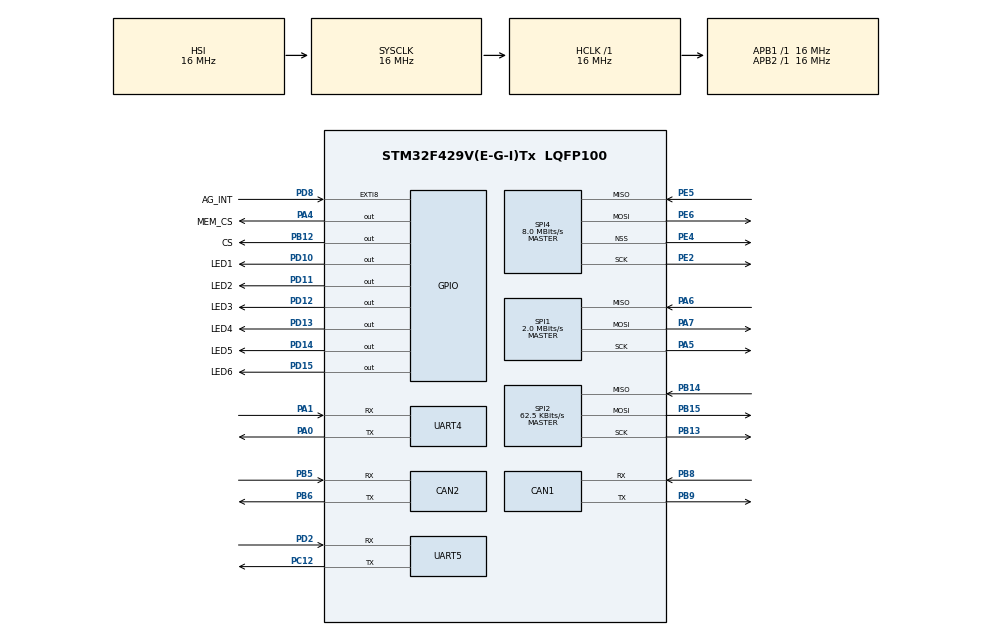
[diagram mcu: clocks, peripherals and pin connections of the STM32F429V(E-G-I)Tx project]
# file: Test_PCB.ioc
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CAN1.BS1=CAN_BS1_1TQ
CAN1.BS2=CAN_BS2_1TQ
CAN1.CalculateTimeBit=3000
CAN1.CalculateTimeQuantum=1000.0
CAN2.BS1=CAN_BS1_1TQ
CAN2.BS2=CAN_BS2_1TQ
CAN2.CalculateTimeBit=3000
CAN2.CalculateTimeQuantum=1000.0
FREERTOS.Tasks01=defaultTask,0,128,StartDefaultTask,Default,NULL
Mcu.Family=STM32F4
Mcu.Name=STM32F429V(E-G-I)Tx
Mcu.Package=LQFP100
NVIC.PriorityGroup=NVIC_PRIORITYGROUP_4
NVIC.TIM1_UP_TIM10_IRQn=true\:0\:0\:false\:false\:true\:false\:false
NVIC.TIM3_IRQn=true\:5\:0\:false\:false\:true\:true\:true
NVIC.TimeBase=TIM1_UP_TIM10_IRQn
NVIC.TimeBaseIP=TIM1
PA0/WKUP.Mode=Asynchronous
PA0/WKUP.Signal=UART4_TX
PA1.Mode=Asynchronous
PA1.Signal=UART4_RX
PA13.Mode=JTAG_5_pins
PA13.Signal=SYS_JTMS-SWDIO
PA14.Mode=JTAG_5_pins
PA14.Signal=SYS_JTCK-SWCLK
PA15.Mode=JTAG_5_pins
PA15.Signal=SYS_JTDI
PA4.GPIO_Label=MEM_CS
PA4.Signal=GPIO_Output
PA5.Mode=Full_Duplex_Master
PA5.Signal=SPI1_SCK
PA6.Mode=Full_Duplex_Master
PA6.Signal=SPI1_MISO
PA7.Mode=Full_Duplex_Master
PA7.Signal=SPI1_MOSI
PB12.GPIO_Label=CS
PB12.Signal=GPIO_Output
PB13.Mode=Full_Duplex_Master
PB13.Signal=SPI2_SCK
PB14.Mode=Full_Duplex_Master
PB14.Signal=SPI2_MISO
PB15.Mode=Full_Duplex_Master
PB15.Signal=SPI2_MOSI
PB3.Mode=JTAG_5_pins
PB3.Signal=SYS_JTDO-SWO
PB4.Mode=JTAG_5_pins
PB4.Signal=SYS_JTRST
PB5.Mode=Slave
PB5.Signal=CAN2_RX
PB6.Mode=Slave
PB6.Signal=CAN2_TX
PB8.Mode=Master
PB8.Signal=CAN1_RX
PB9.Mode=Master
PB9.Signal=CAN1_TX
PC12.Mode=Asynchronous
PC12.Signal=UART5_TX
PD10.GPIO_Label=LED1
PD10.GPIO_PuPd=GPIO_NOPULL
PD10.Signal=GPIO_Output
PD11.GPIO_Label=LED2
PD11.GPIO_PuPd=GPIO_NOPULL
PD11.Signal=GPIO_Output
PD12.GPIO_Label=LED3
PD12.GPIO_PuPd=GPIO_NOPULL
PD12.Signal=GPIO_Output
PD13.GPIO_Label=LED4
PD13.GPIO_PuPd=GPIO_NOPULL
PD13.Signal=GPIO_Output
PD14.GPIO_Label=LED5
PD14.GPIO_PuPd=GPIO_NOPULL
PD14.Signal=GPIO_Output
PD15.GPIO_Label=LED6
PD15.GPIO_PuPd=GPIO_NOPULL
PD15.Signal=GPIO_Output
PD2.Mode=Asynchronous
PD2.Signal=UART5_RX
PD8.GPIO_Label=AG_INT
PD8.GPIO_ModeDefaultEXTI=GPIO_MODE_IT_FALLING
PD8.Signal=GPXTI8
PE2.Mode=Full_Duplex_Master
PE2.Signal=SPI4_SCK
PE4.Mode=NSS_Signal_Hard_Output
PE4.Signal=SPI4_NSS
PE5.Mode=Full_Duplex_Master
PE5.Signal=SPI4_MISO
PE6.Mode=Full_Duplex_Master
PE6.Signal=SPI4_MOSI
PH0/OSC_IN.Mode=HSE-External-Oscillator
PH0/OSC_IN.Signal=RCC_OSC_IN
PH1/OSC_OUT.Mode=HSE-External-Oscillator
PH1/OSC_OUT.Signal=RCC_OSC_OUT
ProjectManager.HeapSize=0x200
ProjectManager.StackSize=0x400
ProjectManager.TargetToolchain=SW4STM32
RCC.AHBFreq_Value=16000000
RCC.APB1Freq_Value=16000000
RCC.APB1TimFreq_Value=16000000
RCC.APB2Freq_Value=16000000
RCC.APB2TimFreq_Value=16000000
RCC.CortexFreq_Value=16000000
RCC.HCLKFreq_Value=16000000
RCC.HSE_VALUE=16000000
RCC.HSI_VALUE=16000000
RCC.LSE_VALUE=32768
RCC.SYSCLKFreq_VALUE=16000000
RCC.VCOOutputFreq_Value=192000000
SPI1.BaudRatePrescaler=SPI_BAUDRATEPRESCALER_8
SPI1.CalculateBaudRate=2.0 MBits/s
SPI1.Direction=SPI_DIRECTION_2LINES
SPI1.Mode=SPI_MODE_MASTER
SPI1.VirtualType=VM_MASTER
SPI2.BaudRatePrescaler=SPI_BAUDRATEPRESCALER_256
SPI2.CalculateBaudRate=62.5 KBits/s
SPI2.DataSize=SPI_DATASIZE_16BIT
SPI2.Direction=SPI_DIRECTION_2LINES
SPI2.Mode=SPI_MODE_MASTER
SPI2.VirtualType=VM_MASTER
SPI4.BaudRatePrescaler=SPI_BAUDRATEPRESCALER_2
SPI4.CalculateBaudRate=8.0 MBits/s
SPI4.Direction=SPI_DIRECTION_2LINES
SPI4.Mode=SPI_MODE_MASTER
SPI4.VirtualNSS=VM_NSSHARD
SPI4.VirtualType=VM_MASTER
TIM3.Period=1000
TIM3.Prescaler=16000
UART4.VirtualMode=Asynchronous
UART5.VirtualMode=Asynchronous
VP_FREERTOS_VS_ENABLE.Mode=Enabled
VP_SYS_VS_tim1.Mode=TIM1
VP_TIM3_VS_ClockSourceINT.Mode=Internal
board=Test_PCB

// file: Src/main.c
/**
  ******************************************************************************
  * File Name          : main.c
  * Description        : Main program body
  ******************************************************************************
  * This notice applies to any and all portions of this file
  * that are not between comment pairs USER CODE BEGIN and
  * USER CODE END. Other portions of this file, whether
  * inserted by the user or by software development tools
  * are owned by their respective copyright owners.
  *
  * Copyright (c) 2018 STMicroelectronics International N.V.
  * All rights reserved.
  *
  * Redistribution and use in source and binary forms, with or without
  * modification, are permitted, provided that the following conditions are met:
  *
  * 1. Redistribution of source code must retain the above copyright notice,
  *    this list of conditions and the following disclaimer.
  * 2. Redistributions in binary form must reproduce the above copyright notice,
  *    this list of conditions and the following disclaimer in the documentation
  *    and/or other materials provided with the distribution.
  * 3. Neither the name of STMicroelectronics nor the names of other
  *    contributors to this software may be used to endorse or promote products
  *    derived from this software without specific written permission.
  * 4. This software, including modifications and/or derivative works of this
  *    software, must execute solely and exclusively on microcontroller or
  *    microprocessor devices manufactured by or for STMicroelectronics.
  * 5. Redistribution and use of this software other than as permitted under
  *    this license is void and will automatically terminate your rights under
  *    this license.
  *
  * THIS SOFTWARE IS PROVIDED BY STMICROELECTRONICS AND CONTRIBUTORS "AS IS"
  * AND ANY EXPRESS, IMPLIED OR STATUTORY WARRANTIES, INCLUDING, BUT NOT
  * LIMITED TO, THE IMPLIED WARRANTIES OF MERCHANTABILITY, FITNESS FOR A
  * PARTICULAR PURPOSE AND NON-INFRINGEMENT OF THIRD PARTY INTELLECTUAL PROPERTY
  * RIGHTS ARE DISCLAIMED TO THE FULLEST EXTENT PERMITTED BY LAW. IN NO EVENT
  * SHALL STMICROELECTRONICS OR CONTRIBUTORS BE LIABLE FOR ANY DIRECT, INDIRECT,
  * INCIDENTAL, SPECIAL, EXEMPLARY, OR CONSEQUENTIAL DAMAGES (INCLUDING, BUT NOT
  * LIMITED TO, PROCUREMENT OF SUBSTITUTE GOODS OR SERVICES; LOSS OF USE, DATA,
  * OR PROFITS; OR BUSINESS INTERRUPTION) HOWEVER CAUSED AND ON ANY THEORY OF
  * LIABILITY, WHETHER IN CONTRACT, STRICT LIABILITY, OR TORT (INCLUDING
  * NEGLIGENCE OR OTHERWISE) ARISING IN ANY WAY OUT OF THE USE OF THIS SOFTWARE,
  * EVEN IF ADVISED OF THE POSSIBILITY OF SUCH DAMAGE.
  *
  ******************************************************************************
  */
#include "mems.h"
#include "debug.h"
#include "main.h"
#include "stm32f4xx_hal.h"
#include "cmsis_os.h"

/* USER CODE BEGIN Includes */
//#include "gyro.h"
//#include "memory.h"
/* USER CODE END Includes */

CAN_HandleTypeDef hcan1;
CAN_HandleTypeDef hcan2;

SPI_HandleTypeDef hspi1;
SPI_HandleTypeDef hspi2;
SPI_HandleTypeDef hspi4;

TIM_HandleTypeDef htim3;

UART_HandleTypeDef huart4;
UART_HandleTypeDef huart5;

osThreadId defaultTaskHandle;

/* USER CODE BEGIN PV */
/* Private variables ---------------------------------------------------------*/
int tgl=0;
char test[64];
osThreadId receiveUARTHandle;
osThreadId sendUARTHandle;
/* USER CODE END PV */

void SystemClock_Config(void);
static void MX_GPIO_Init(void);
static void MX_CAN1_Init(void);
static void MX_CAN2_Init(void);
static void MX_SPI1_Init(void);
static void MX_UART4_Init(void);
static void MX_UART5_Init(void);
static void MX_SPI4_Init(void);
static void MX_SPI2_Init(void);
static void MX_TIM3_Init(void);
void StartDefaultTask(void const * argument);

/* USER CODE BEGIN PFP */
/* Private function prototypes -----------------------------------------------*/
//void receiveUARTTask(void const * argument);
//void sendUARTTask(void const * argument);
/* USER CODE END PFP */

int main(void)
{

  /* MCU Configuration----------------------------------------------------------*/

  /* Reset of all peripherals, Initializes the Flash interface and the Systick. */
  HAL_Init();

  /* Configure the system clock */
  SystemClock_Config();

  /* Initialize all configured peripherals */
  MX_GPIO_Init();
  MX_CAN1_Init();
  MX_CAN2_Init();
  MX_SPI1_Init();
  MX_UART4_Init();
  MX_UART5_Init();
  MX_SPI4_Init();
  MX_SPI2_Init();
  MX_TIM3_Init();

  /* USER CODE BEGIN 2 */
  mems_init8b(&huart4,&hspi2); //init gyro

  /* USER CODE END 2 */

  /* Create the thread(s) */
  /* definition and creation of defaultTask */
  osThreadDef(defaultTask, StartDefaultTask, osPriorityNormal, 0, 128);
  defaultTaskHandle = osThreadCreate(osThread(defaultTask), NULL);

  /* USER CODE BEGIN RTOS_THREADS */
  /* add threads, ... */

//  osThreadDef(receiveTask, receiveUARTTask, osPriorityNormal, 0, 128);
//  receiveUARTHandle = osThreadCreate(osThread(receiveTask), NULL);
//
//  osThreadDef(sendTask, sendUARTTask, osPriorityNormal, 0, 128);
//  sendUARTHandle = osThreadCreate(osThread(sendTask), NULL);

  /* USER CODE END RTOS_THREADS */

  /* Start scheduler */
  osKernelStart();

  /* We should never get here as control is now taken by the scheduler */

  /* Infinite loop */
  while (1)
  {

  /* USER CODE BEGIN 3 */
	  HAL_GPIO_WritePin(GPIOD, GPIO_PIN_10, 1);
  }
  /* USER CODE END 3 */

}

/** System Clock Configuration
*/
void SystemClock_Config(void)
{

  RCC_OscInitTypeDef RCC_OscInitStruct;
  RCC_ClkInitTypeDef RCC_ClkInitStruct;

    /**Configure the main internal regulator output voltage
    */
  __HAL_RCC_PWR_CLK_ENABLE();

  __HAL_PWR_VOLTAGESCALING_CONFIG(PWR_REGULATOR_VOLTAGE_SCALE3);

    /**Initializes the CPU, AHB and APB busses clocks
    */
  RCC_OscInitStruct.OscillatorType = RCC_OSCILLATORTYPE_HSI;
  RCC_OscInitStruct.HSIState = RCC_HSI_ON;
  RCC_OscInitStruct.HSICalibrationValue = 16;
  RCC_OscInitStruct.PLL.PLLState = RCC_PLL_NONE;
  if (HAL_RCC_OscConfig(&RCC_OscInitStruct) != HAL_OK)
  {
    _Error_Handler(__FILE__, __LINE__);
  }

    /**Initializes the CPU, AHB and APB busses clocks
    */
  RCC_ClkInitStruct.ClockType = RCC_CLOCKTYPE_HCLK|RCC_CLOCKTYPE_SYSCLK
                              |RCC_CLOCKTYPE_PCLK1|RCC_CLOCKTYPE_PCLK2;
  RCC_ClkInitStruct.SYSCLKSource = RCC_SYSCLKSOURCE_HSI;
  RCC_ClkInitStruct.AHBCLKDivider = RCC_SYSCLK_DIV1;
  RCC_ClkInitStruct.APB1CLKDivider = RCC_HCLK_DIV1;
  RCC_ClkInitStruct.APB2CLKDivider = RCC_HCLK_DIV1;

  if (HAL_RCC_ClockConfig(&RCC_ClkInitStruct, FLASH_LATENCY_0) != HAL_OK)
  {
    _Error_Handler(__FILE__, __LINE__);
  }

    /**Configure the Systick interrupt time
    */
  HAL_SYSTICK_Config(HAL_RCC_GetHCLKFreq()/1000);

    /**Configure the Systick
    */
  HAL_SYSTICK_CLKSourceConfig(SYSTICK_CLKSOURCE_HCLK);

  /* SysTick_IRQn interrupt configuration */
  HAL_NVIC_SetPriority(SysTick_IRQn, 15, 0);
}

/* CAN1 init function */
static void MX_CAN1_Init(void)
{

  hcan1.Instance = CAN1;
  hcan1.Init.Prescaler = 16;
  hcan1.Init.Mode = CAN_MODE_NORMAL;
  hcan1.Init.SJW = CAN_SJW_1TQ;
  hcan1.Init.BS1 = CAN_BS1_1TQ;
  hcan1.Init.BS2 = CAN_BS2_1TQ;
  hcan1.Init.TTCM = DISABLE;
  hcan1.Init.ABOM = DISABLE;
  hcan1.Init.AWUM = DISABLE;
  hcan1.Init.NART = DISABLE;
  hcan1.Init.RFLM = DISABLE;
  hcan1.Init.TXFP = DISABLE;
  if (HAL_CAN_Init(&hcan1) != HAL_OK)
  {
    _Error_Handler(__FILE__, __LINE__);
  }

}

/* CAN2 init function */
static void MX_CAN2_Init(void)
{

  hcan2.Instance = CAN2;
  hcan2.Init.Prescaler = 16;
  hcan2.Init.Mode = CAN_MODE_NORMAL;
  hcan2.Init.SJW = CAN_SJW_1TQ;
  hcan2.Init.BS1 = CAN_BS1_1TQ;
  hcan2.Init.BS2 = CAN_BS2_1TQ;
  hcan2.Init.TTCM = DISABLE;
  hcan2.Init.ABOM = DISABLE;
  hcan2.Init.AWUM = DISABLE;
  hcan2.Init.NART = DISABLE;
  hcan2.Init.RFLM = DISABLE;
  hcan2.Init.TXFP = DISABLE;
  if (HAL_CAN_Init(&hcan2) != HAL_OK)
  {
    _Error_Handler(__FILE__, __LINE__);
  }

}

/* SPI1 init function */
static void MX_SPI1_Init(void)
{

  /* SPI1 parameter configuration*/
  hspi1.Instance = SPI1;
  hspi1.Init.Mode = SPI_MODE_MASTER;
  hspi1.Init.Direction = SPI_DIRECTION_2LINES;
  hspi1.Init.DataSize = SPI_DATASIZE_8BIT;
  hspi1.Init.CLKPolarity = SPI_POLARITY_LOW;
  hspi1.Init.CLKPhase = SPI_PHASE_1EDGE;
  hspi1.Init.NSS = SPI_NSS_SOFT;
  hspi1.Init.BaudRatePrescaler = SPI_BAUDRATEPRESCALER_8;
  hspi1.Init.FirstBit = SPI_FIRSTBIT_MSB;
  hspi1.Init.TIMode = SPI_TIMODE_DISABLE;
  hspi1.Init.CRCCalculation = SPI_CRCCALCULATION_DISABLE;
  hspi1.Init.CRCPolynomial = 10;
  if (HAL_SPI_Init(&hspi1) != HAL_OK)
  {
    _Error_Handler(__FILE__, __LINE__);
  }

}

/* SPI2 init function */
static void MX_SPI2_Init(void)
{

  /* SPI2 parameter configuration*/
  hspi2.Instance = SPI2;
  hspi2.Init.Mode = SPI_MODE_MASTER;
  hspi2.Init.Direction = SPI_DIRECTION_2LINES;
  hspi2.Init.DataSize = SPI_DATASIZE_8BIT;
  hspi2.Init.CLKPolarity = SPI_POLARITY_LOW;
  hspi2.Init.CLKPhase = SPI_PHASE_1EDGE;
  hspi2.Init.NSS = SPI_NSS_SOFT;
  hspi2.Init.BaudRatePrescaler = SPI_BAUDRATEPRESCALER_64; //max around 16
  hspi2.Init.FirstBit = SPI_FIRSTBIT_MSB;
  hspi2.Init.TIMode = SPI_TIMODE_DISABLE;
  hspi2.Init.CRCCalculation = SPI_CRCCALCULATION_DISABLE;
  hspi2.Init.CRCPolynomial = 10;
  if (HAL_SPI_Init(&hspi2) != HAL_OK)
  {
    _Error_Handler(__FILE__, __LINE__);
  }

}

/* SPI4 init function */
static void MX_SPI4_Init(void)
{

  /* SPI4 parameter configuration*/
  hspi4.Instance = SPI4;
  hspi4.Init.Mode = SPI_MODE_MASTER;
  hspi4.Init.Direction = SPI_DIRECTION_2LINES;
  hspi4.Init.DataSize = SPI_DATASIZE_8BIT;
  hspi4.Init.CLKPolarity = SPI_POLARITY_LOW;
  hspi4.Init.CLKPhase = SPI_PHASE_1EDGE;
  hspi4.Init.NSS = SPI_NSS_HARD_OUTPUT;
  hspi4.Init.BaudRatePrescaler = SPI_BAUDRATEPRESCALER_2;
  hspi4.Init.FirstBit = SPI_FIRSTBIT_MSB;
  hspi4.Init.TIMode = SPI_TIMODE_DISABLE;
  hspi4.Init.CRCCalculation = SPI_CRCCALCULATION_DISABLE;
  hspi4.Init.CRCPolynomial = 10;
  if (HAL_SPI_Init(&hspi4) != HAL_OK)
  {
    _Error_Handler(__FILE__, __LINE__);
  }

}

/* TIM3 init function */
static void MX_TIM3_Init(void)
{

  TIM_ClockConfigTypeDef sClockSourceConfig;
  TIM_MasterConfigTypeDef sMasterConfig;

  htim3.Instance = TIM3;
  htim3.Init.Prescaler = 16000;
  htim3.Init.CounterMode = TIM_COUNTERMODE_UP;
  htim3.Init.Period = 1000;
  htim3.Init.ClockDivision = TIM_CLOCKDIVISION_DIV1;
  if (HAL_TIM_Base_Init(&htim3) != HAL_OK)
  {
    _Error_Handler(__FILE__, __LINE__);
  }

  sClockSourceConfig.ClockSource = TIM_CLOCKSOURCE_INTERNAL;
  if (HAL_TIM_ConfigClockSource(&htim3, &sClockSourceConfig) != HAL_OK)
  {
    _Error_Handler(__FILE__, __LINE__);
  }

  sMasterConfig.MasterOutputTrigger = TIM_TRGO_RESET;
  sMasterConfig.MasterSlaveMode = TIM_MASTERSLAVEMODE_DISABLE;
  if (HAL_TIMEx_MasterConfigSynchronization(&htim3, &sMasterConfig) != HAL_OK)
  {
    _Error_Handler(__FILE__, __LINE__);
  }

}

/* UART4 init function */
static void MX_UART4_Init(void)
{

  huart4.Instance = UART4;
  huart4.Init.BaudRate = 115200;
  huart4.Init.WordLength = UART_WORDLENGTH_8B;
  huart4.Init.StopBits = UART_STOPBITS_1;
  huart4.Init.Parity = UART_PARITY_NONE;
  huart4.Init.Mode = UART_MODE_TX_RX;
  huart4.Init.HwFlowCtl = UART_HWCONTROL_NONE;
  huart4.Init.OverSampling = UART_OVERSAMPLING_16;
  if (HAL_UART_Init(&huart4) != HAL_OK)
  {
    _Error_Handler(__FILE__, __LINE__);
  }

}

/* UART5 init function */
static void MX_UART5_Init(void)
{

  huart5.Instance = UART5;
  huart5.Init.BaudRate = 115200;
  huart5.Init.WordLength = UART_WORDLENGTH_8B;
  huart5.Init.StopBits = UART_STOPBITS_1;
  huart5.Init.Parity = UART_PARITY_NONE;
  huart5.Init.Mode = UART_MODE_TX_RX;
  huart5.Init.HwFlowCtl = UART_HWCONTROL_NONE;
  huart5.Init.OverSampling = UART_OVERSAMPLING_16;
  if (HAL_UART_Init(&huart5) != HAL_OK)
  {
    _Error_Handler(__FILE__, __LINE__);
  }

}

/** Configure pins as
        * Analog
        * Input
        * Output
        * EVENT_OUT
        * EXTI
        * Free pins are configured automatically as Analog (this feature is enabled through
        * the Code Generation settings)
*/
static void MX_GPIO_Init(void)
{

  GPIO_InitTypeDef GPIO_InitStruct;

  /* GPIO Ports Clock Enable */
  __HAL_RCC_GPIOE_CLK_ENABLE();
  __HAL_RCC_GPIOC_CLK_ENABLE();
  __HAL_RCC_GPIOH_CLK_ENABLE();
  __HAL_RCC_GPIOA_CLK_ENABLE();
  __HAL_RCC_GPIOB_CLK_ENABLE();
  __HAL_RCC_GPIOD_CLK_ENABLE();

  /*Configure GPIO pin Output Level */
  HAL_GPIO_WritePin(MEM_CS_GPIO_Port, MEM_CS_Pin, GPIO_PIN_RESET);

  /*Configure GPIO pin Output Level */
  HAL_GPIO_WritePin(CS_GPIO_Port, CS_Pin, GPIO_PIN_RESET);

  /*Configure GPIO pin Output Level */
  HAL_GPIO_WritePin(GPIOD, LED1_Pin|LED2_Pin|LED3_Pin|LED4_Pin
                          |LED5_Pin|LED6_Pin, GPIO_PIN_RESET);

  /*Configure GPIO pins : PE3 PE7 PE8 PE9
                           PE10 PE11 PE12 PE13
                           PE14 PE15 PE0 PE1 */
  GPIO_InitStruct.Pin = GPIO_PIN_3|GPIO_PIN_7|GPIO_PIN_8|GPIO_PIN_9
                          |GPIO_PIN_10|GPIO_PIN_11|GPIO_PIN_12|GPIO_PIN_13
                          |GPIO_PIN_14|GPIO_PIN_15|GPIO_PIN_0|GPIO_PIN_1;
  GPIO_InitStruct.Mode = GPIO_MODE_ANALOG;
  GPIO_InitStruct.Pull = GPIO_NOPULL;
  HAL_GPIO_Init(GPIOE, &GPIO_InitStruct);

  /*Configure GPIO pins : PC13 PC14 PC15 PC0
                           PC1 PC2 PC3 PC4
                           PC5 PC6 PC7 PC8
                           PC9 PC10 PC11 */
  GPIO_InitStruct.Pin = GPIO_PIN_13|GPIO_PIN_14|GPIO_PIN_15|GPIO_PIN_0
                          |GPIO_PIN_1|GPIO_PIN_2|GPIO_PIN_3|GPIO_PIN_4
                          |GPIO_PIN_5|GPIO_PIN_6|GPIO_PIN_7|GPIO_PIN_8
                          |GPIO_PIN_9|GPIO_PIN_10|GPIO_PIN_11;
  GPIO_InitStruct.Mode = GPIO_MODE_ANALOG;
  GPIO_InitStruct.Pull = GPIO_NOPULL;
  HAL_GPIO_Init(GPIOC, &GPIO_InitStruct);

  /*Configure GPIO pins : PA2 PA3 PA8 PA9
                           PA10 PA11 PA12 */
  GPIO_InitStruct.Pin = GPIO_PIN_2|GPIO_PIN_3|GPIO_PIN_8|GPIO_PIN_9
                          |GPIO_PIN_10|GPIO_PIN_11|GPIO_PIN_12;
  GPIO_InitStruct.Mode = GPIO_MODE_ANALOG;
  GPIO_InitStruct.Pull = GPIO_NOPULL;
  HAL_GPIO_Init(GPIOA, &GPIO_InitStruct);

  /*Configure GPIO pin : MEM_CS_Pin */
  GPIO_InitStruct.Pin = MEM_CS_Pin;
  GPIO_InitStruct.Mode = GPIO_MODE_OUTPUT_PP;
  GPIO_InitStruct.Pull = GPIO_NOPULL;
  GPIO_InitStruct.Speed = GPIO_SPEED_FREQ_LOW;
  HAL_GPIO_Init(MEM_CS_GPIO_Port, &GPIO_InitStruct);

  /*Configure GPIO pins : PB0 PB1 PB2 PB10
                           PB11 PB7 */
  GPIO_InitStruct.Pin = GPIO_PIN_0|GPIO_PIN_1|GPIO_PIN_2|GPIO_PIN_10
                          |GPIO_PIN_11|GPIO_PIN_7;
  GPIO_InitStruct.Mode = GPIO_MODE_ANALOG;
  GPIO_InitStruct.Pull = GPIO_NOPULL;
  HAL_GPIO_Init(GPIOB, &GPIO_InitStruct);

  /*Configure GPIO pin : CS_Pin */
  GPIO_InitStruct.Pin = CS_Pin;
  GPIO_InitStruct.Mode = GPIO_MODE_OUTPUT_PP;
  GPIO_InitStruct.Pull = GPIO_NOPULL;
  GPIO_InitStruct.Speed = GPIO_SPEED_FREQ_LOW;
  HAL_GPIO_Init(CS_GPIO_Port, &GPIO_InitStruct);

  /*Configure GPIO pin : AG_INT_Pin */
  GPIO_InitStruct.Pin = AG_INT_Pin;
  GPIO_InitStruct.Mode = GPIO_MODE_IT_FALLING;
  GPIO_InitStruct.Pull = GPIO_NOPULL;
  HAL_GPIO_Init(AG_INT_GPIO_Port, &GPIO_InitStruct);

  /*Configure GPIO pins : PD9 PD0 PD1 PD3
                           PD4 PD5 PD6 PD7 */
  GPIO_InitStruct.Pin = GPIO_PIN_9|GPIO_PIN_0|GPIO_PIN_1|GPIO_PIN_3
                          |GPIO_PIN_4|GPIO_PIN_5|GPIO_PIN_6|GPIO_PIN_7;
  GPIO_InitStruct.Mode = GPIO_MODE_ANALOG;
  GPIO_InitStruct.Pull = GPIO_NOPULL;
  HAL_GPIO_Init(GPIOD, &GPIO_InitStruct);

  /*Configure GPIO pins : LED1_Pin LED2_Pin LED3_Pin LED4_Pin
                           LED5_Pin LED6_Pin */
  GPIO_InitStruct.Pin = LED1_Pin|LED2_Pin|LED3_Pin|LED4_Pin
                          |LED5_Pin|LED6_Pin;
  GPIO_InitStruct.Mode = GPIO_MODE_OUTPUT_PP;
  GPIO_InitStruct.Pull = GPIO_NOPULL;
  GPIO_InitStruct.Speed = GPIO_SPEED_FREQ_LOW;
  HAL_GPIO_Init(GPIOD, &GPIO_InitStruct);

}

int16_t res;
int16_t results[3];
/* StartDefaultTask function */
void StartDefaultTask(void const * argument)
{

  /* USER CODE BEGIN 5 */
  /* Infinite loop */
  for(;;)
  {

	  acc_three_axis_read(results, &huart4,&hspi2);
	  res=mems_quick_read(ACC_YOH,&huart4,&hspi2);
//	  char_Print(&huart4,"single x: ");
//	  signed_print(&huart4,res);
	  char text[30];
	  sprintf(text,"3 axx:%d single:%d \n ",results[0],res);
	  char_Print(&huart4,text);

	  osDelay(100); //20ms  repeating function
  }
}
  /* USER CODE END 5 */

void HAL_TIM_PeriodElapsedCallback(TIM_HandleTypeDef *htim)
{
  if (htim->Instance == TIM1) {
    HAL_IncTick();
  }
}

void _Error_Handler(char * file, int line)
{
  while(1)
  {
  }
}
